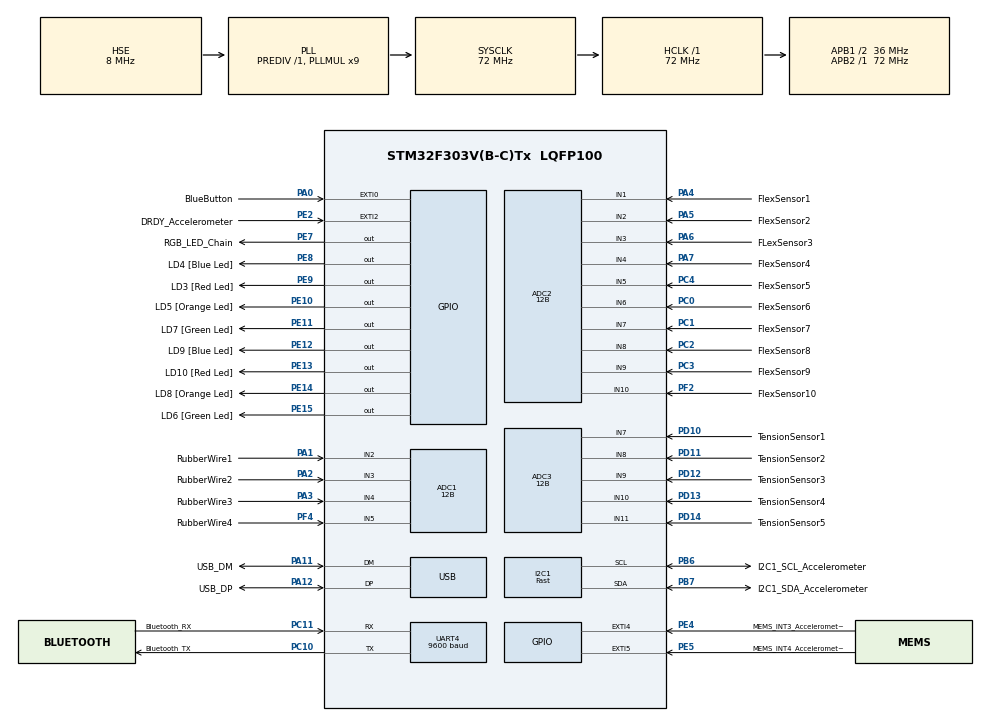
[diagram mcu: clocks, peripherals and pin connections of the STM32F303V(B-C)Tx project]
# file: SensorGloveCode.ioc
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ADC1.Channel-0\#ChannelRegularConversion=ADC_CHANNEL_2
ADC1.Channel-1\#ChannelRegularConversion=ADC_CHANNEL_3
ADC1.Channel-2\#ChannelRegularConversion=ADC_CHANNEL_4
ADC1.Channel-3\#ChannelRegularConversion=ADC_CHANNEL_5
ADC1.ClockPrescaler=ADC_CLOCK_SYNC_PCLK_DIV1
ADC1.ContinuousConvMode=ENABLE
ADC1.DMAContinuousRequests=ENABLE
ADC1.DataAlign=ADC_DATAALIGN_RIGHT
ADC1.DiscontinuousConvMode=DISABLE
ADC1.EOCSelection=ADC_EOC_SEQ_CONV
ADC1.EnableAnalogWatchDog1=false
ADC1.EnableAnalogWatchDog2=false
ADC1.EnableAnalogWatchDog3=false
ADC1.EnableInjectedConversion=ENABLE
ADC1.EnableRegularConversion=ENABLE
ADC1.ExternalTrigConv=ADC_SOFTWARE_START
ADC1.ExternalTrigConvEdge=ADC_EXTERNALTRIGCONVEDGE_NONE
ADC1.InjNumberOfConversion=0
ADC1.LowPowerAutoWait=DISABLE
ADC1.NbrOfConversion=4
ADC1.NbrOfConversionFlag=1
ADC1.Offset-0\#ChannelRegularConversion=0
ADC1.Offset-1\#ChannelRegularConversion=0
ADC1.Offset-2\#ChannelRegularConversion=0
ADC1.Offset-3\#ChannelRegularConversion=0
ADC1.OffsetNumber-0\#ChannelRegularConversion=ADC_OFFSET_NONE
ADC1.OffsetNumber-1\#ChannelRegularConversion=ADC_OFFSET_NONE
ADC1.OffsetNumber-2\#ChannelRegularConversion=ADC_OFFSET_NONE
ADC1.OffsetNumber-3\#ChannelRegularConversion=ADC_OFFSET_NONE
ADC1.Overrun=ADC_OVR_DATA_OVERWRITTEN
ADC1.Rank-0\#ChannelRegularConversion=1
ADC1.Rank-1\#ChannelRegularConversion=2
ADC1.Rank-2\#ChannelRegularConversion=3
ADC1.Rank-3\#ChannelRegularConversion=4
ADC1.Resolution=ADC_RESOLUTION_12B
ADC1.SamplingTime-0\#ChannelRegularConversion=ADC_SAMPLETIME_181CYCLES_5
ADC1.SamplingTime-1\#ChannelRegularConversion=ADC_SAMPLETIME_181CYCLES_5
ADC1.SamplingTime-2\#ChannelRegularConversion=ADC_SAMPLETIME_181CYCLES_5
ADC1.SamplingTime-3\#ChannelRegularConversion=ADC_SAMPLETIME_181CYCLES_5
ADC1.ScanConvMode=ADC_SCAN_ENABLE
ADC1.master=1
ADC2.Channel-0\#ChannelRegularConversion=ADC_CHANNEL_1
ADC2.Channel-1\#ChannelRegularConversion=ADC_CHANNEL_2
ADC2.Channel-2\#ChannelRegularConversion=ADC_CHANNEL_3
ADC2.Channel-3\#ChannelRegularConversion=ADC_CHANNEL_4
ADC2.Channel-4\#ChannelRegularConversion=ADC_CHANNEL_5
ADC2.Channel-5\#ChannelRegularConversion=ADC_CHANNEL_6
ADC2.Channel-6\#ChannelRegularConversion=ADC_CHANNEL_7
ADC2.Channel-7\#ChannelRegularConversion=ADC_CHANNEL_8
ADC2.Channel-8\#ChannelRegularConversion=ADC_CHANNEL_9
ADC2.Channel-9\#ChannelRegularConversion=ADC_CHANNEL_10
ADC2.ClockPrescaler=ADC_CLOCK_SYNC_PCLK_DIV1
ADC2.ContinuousConvMode=ENABLE
ADC2.DMAContinuousRequests=ENABLE
ADC2.DataAlign=ADC_DATAALIGN_RIGHT
ADC2.DiscontinuousConvMode=DISABLE
ADC2.EOCSelection=ADC_EOC_SEQ_CONV
ADC2.EnableAnalogWatchDog1=false
ADC2.EnableAnalogWatchDog2=false
ADC2.EnableAnalogWatchDog3=false
ADC2.EnableInjectedConversion=ENABLE
ADC2.EnableRegularConversion=ENABLE
ADC2.ExternalTrigConv=ADC_SOFTWARE_START
ADC2.ExternalTrigConvEdge=ADC_EXTERNALTRIGCONVEDGE_NONE
ADC2.InjNumberOfConversion=0
ADC2.LowPowerAutoWait=DISABLE
ADC2.NbrOfConversion=10
ADC2.NbrOfConversionFlag=1
ADC2.Offset-0\#ChannelRegularConversion=0
ADC2.Offset-1\#ChannelRegularConversion=0
ADC2.Offset-2\#ChannelRegularConversion=0
ADC2.Offset-3\#ChannelRegularConversion=0
ADC2.Offset-4\#ChannelRegularConversion=0
ADC2.Offset-5\#ChannelRegularConversion=0
ADC2.Offset-6\#ChannelRegularConversion=0
ADC2.Offset-7\#ChannelRegularConversion=0
ADC2.Offset-8\#ChannelRegularConversion=0
ADC2.Offset-9\#ChannelRegularConversion=0
ADC2.OffsetNumber-0\#ChannelRegularConversion=ADC_OFFSET_NONE
ADC2.OffsetNumber-1\#ChannelRegularConversion=ADC_OFFSET_NONE
ADC2.OffsetNumber-2\#ChannelRegularConversion=ADC_OFFSET_NONE
ADC2.OffsetNumber-3\#ChannelRegularConversion=ADC_OFFSET_NONE
ADC2.OffsetNumber-4\#ChannelRegularConversion=ADC_OFFSET_NONE
ADC2.OffsetNumber-5\#ChannelRegularConversion=ADC_OFFSET_NONE
ADC2.OffsetNumber-6\#ChannelRegularConversion=ADC_OFFSET_NONE
ADC2.OffsetNumber-7\#ChannelRegularConversion=ADC_OFFSET_NONE
ADC2.OffsetNumber-8\#ChannelRegularConversion=ADC_OFFSET_NONE
ADC2.OffsetNumber-9\#ChannelRegularConversion=ADC_OFFSET_NONE
ADC2.Overrun=ADC_OVR_DATA_OVERWRITTEN
ADC2.Rank-0\#ChannelRegularConversion=1
ADC2.Rank-1\#ChannelRegularConversion=2
ADC2.Rank-2\#ChannelRegularConversion=3
ADC2.Rank-3\#ChannelRegularConversion=4
ADC2.Rank-4\#ChannelRegularConversion=5
ADC2.Rank-5\#ChannelRegularConversion=6
ADC2.Rank-6\#ChannelRegularConversion=7
ADC2.Rank-7\#ChannelRegularConversion=8
ADC2.Rank-8\#ChannelRegularConversion=9
ADC2.Rank-9\#ChannelRegularConversion=10
ADC2.Resolution=ADC_RESOLUTION_12B
ADC2.SamplingTime-0\#ChannelRegularConversion=ADC_SAMPLETIME_181CYCLES_5
ADC2.SamplingTime-1\#ChannelRegularConversion=ADC_SAMPLETIME_181CYCLES_5
ADC2.SamplingTime-2\#ChannelRegularConversion=ADC_SAMPLETIME_181CYCLES_5
ADC2.SamplingTime-3\#ChannelRegularConversion=ADC_SAMPLETIME_181CYCLES_5
ADC2.SamplingTime-4\#ChannelRegularConversion=ADC_SAMPLETIME_181CYCLES_5
ADC2.SamplingTime-5\#ChannelRegularConversion=ADC_SAMPLETIME_181CYCLES_5
ADC2.SamplingTime-6\#ChannelRegularConversion=ADC_SAMPLETIME_181CYCLES_5
ADC2.SamplingTime-7\#ChannelRegularConversion=ADC_SAMPLETIME_181CYCLES_5
ADC2.SamplingTime-8\#ChannelRegularConversion=ADC_SAMPLETIME_181CYCLES_5
ADC2.SamplingTime-9\#ChannelRegularConversion=ADC_SAMPLETIME_181CYCLES_5
ADC2.ScanConvMode=ADC_SCAN_ENABLE
ADC3.Channel-13\#ChannelRegularConversion=ADC_CHANNEL_7
ADC3.Channel-14\#ChannelRegularConversion=ADC_CHANNEL_8
ADC3.Channel-15\#ChannelRegularConversion=ADC_CHANNEL_9
ADC3.Channel-16\#ChannelRegularConversion=ADC_CHANNEL_10
ADC3.Channel-17\#ChannelRegularConversion=ADC_CHANNEL_11
ADC3.ClockPrescaler=ADC_CLOCK_SYNC_PCLK_DIV1
ADC3.ContinuousConvMode=ENABLE
ADC3.DMAContinuousRequests=ENABLE
ADC3.DataAlign=ADC_DATAALIGN_RIGHT
ADC3.DiscontinuousConvMode=DISABLE
ADC3.EOCSelection=ADC_EOC_SEQ_CONV
ADC3.EnableAnalogWatchDog1=false
ADC3.EnableAnalogWatchDog2=false
ADC3.EnableAnalogWatchDog3=false
ADC3.EnableInjectedConversion=ENABLE
ADC3.EnableRegularConversion=ENABLE
ADC3.ExternalTrigConv=ADC_SOFTWARE_START
ADC3.ExternalTrigConvEdge=ADC_EXTERNALTRIGCONVEDGE_NONE
ADC3.InjNumberOfConversion=0
ADC3.LowPowerAutoWait=DISABLE
ADC3.NbrOfConversion=5
ADC3.NbrOfConversionFlag=1
ADC3.Offset-13\#ChannelRegularConversion=0
ADC3.Offset-14\#ChannelRegularConversion=0
ADC3.Offset-15\#ChannelRegularConversion=0
ADC3.Offset-16\#ChannelRegularConversion=0
ADC3.Offset-17\#ChannelRegularConversion=0
ADC3.OffsetNumber-13\#ChannelRegularConversion=ADC_OFFSET_NONE
ADC3.OffsetNumber-14\#ChannelRegularConversion=ADC_OFFSET_NONE
ADC3.OffsetNumber-15\#ChannelRegularConversion=ADC_OFFSET_NONE
ADC3.OffsetNumber-16\#ChannelRegularConversion=ADC_OFFSET_NONE
ADC3.OffsetNumber-17\#ChannelRegularConversion=ADC_OFFSET_NONE
ADC3.Overrun=ADC_OVR_DATA_OVERWRITTEN
ADC3.Rank-13\#ChannelRegularConversion=1
ADC3.Rank-14\#ChannelRegularConversion=2
ADC3.Rank-15\#ChannelRegularConversion=3
ADC3.Rank-16\#ChannelRegularConversion=4
ADC3.Rank-17\#ChannelRegularConversion=5
ADC3.Resolution=ADC_RESOLUTION_12B
ADC3.SamplingTime-13\#ChannelRegularConversion=ADC_SAMPLETIME_181CYCLES_5
ADC3.SamplingTime-14\#ChannelRegularConversion=ADC_SAMPLETIME_181CYCLES_5
ADC3.SamplingTime-15\#ChannelRegularConversion=ADC_SAMPLETIME_181CYCLES_5
ADC3.SamplingTime-16\#ChannelRegularConversion=ADC_SAMPLETIME_181CYCLES_5
ADC3.SamplingTime-17\#ChannelRegularConversion=ADC_SAMPLETIME_181CYCLES_5
ADC3.ScanConvMode=ADC_SCAN_ENABLE
ADC3.master=1
Dma.ADC1.2.Direction=DMA_PERIPH_TO_MEMORY
Dma.ADC1.2.Instance=DMA1_Channel1
Dma.ADC1.2.MemDataAlignment=DMA_MDATAALIGN_HALFWORD
Dma.ADC1.2.MemInc=DMA_MINC_ENABLE
Dma.ADC1.2.Mode=DMA_CIRCULAR
Dma.ADC1.2.PeriphDataAlignment=DMA_PDATAALIGN_HALFWORD
Dma.ADC1.2.PeriphInc=DMA_PINC_DISABLE
Dma.ADC1.2.Priority=DMA_PRIORITY_LOW
Dma.ADC2.1.Direction=DMA_PERIPH_TO_MEMORY
Dma.ADC2.1.Instance=DMA2_Channel3
Dma.ADC2.1.MemDataAlignment=DMA_MDATAALIGN_HALFWORD
Dma.ADC2.1.MemInc=DMA_MINC_ENABLE
Dma.ADC2.1.Mode=DMA_CIRCULAR
Dma.ADC2.1.PeriphDataAlignment=DMA_PDATAALIGN_HALFWORD
Dma.ADC2.1.PeriphInc=DMA_PINC_DISABLE
Dma.ADC2.1.Priority=DMA_PRIORITY_LOW
Dma.ADC3.0.Direction=DMA_PERIPH_TO_MEMORY
Dma.ADC3.0.Instance=DMA2_Channel5
Dma.ADC3.0.MemDataAlignment=DMA_MDATAALIGN_HALFWORD
Dma.ADC3.0.MemInc=DMA_MINC_ENABLE
Dma.ADC3.0.Mode=DMA_CIRCULAR
Dma.ADC3.0.PeriphDataAlignment=DMA_PDATAALIGN_HALFWORD
Dma.ADC3.0.PeriphInc=DMA_PINC_DISABLE
Dma.ADC3.0.Priority=DMA_PRIORITY_LOW
Dma.Request0=ADC3
Dma.Request1=ADC2
Dma.Request2=ADC1
I2C1.I2C_Speed_Mode=I2C_Fast
I2C1.Speed=I2C_ClockSpeed_kHz
I2C1.Timing=0x0000020B
Mcu.Family=STM32F3
Mcu.Name=STM32F303V(B-C)Tx
Mcu.Package=LQFP100
Mcu.UserConstants=I2C_ClockSpeed_kHz,400;TIM6_PRESCALER,71;TIM6_COUNTER_PERIOD,99;TIM7_PRESCALER,719;TIM7_COUNTER_PERIOD,99
NVIC.DMA1_Channel1_IRQn=true\:0\:0\:false\:false\:true
NVIC.DMA2_Channel3_IRQn=true\:0\:0\:false\:false\:true
NVIC.DMA2_Channel5_IRQn=true\:0\:0\:false\:false\:true
NVIC.EXTI0_IRQn=true\:0\:0\:false\:false\:true
NVIC.PriorityGroup=NVIC_PRIORITYGROUP_0
NVIC.TIM6_DAC_IRQn=true\:0\:0\:false\:false\:true
NVIC.TIM7_IRQn=true\:0\:0\:false\:false\:true
NVIC.UART4_IRQn=true\:0\:0\:false\:false\:true
NVIC.USB_LP_CAN_RX0_IRQn=true\:0\:0\:false\:false\:true
PA0.GPIO_Label=BlueButton
PA0.GPIO_ModeDefaultEXTI=GPIO_MODE_IT_RISING
PA0.GPIO_PuPd=GPIO_PULLDOWN
PA0.Signal=GPXTI0
PA1.GPIO_Label=RubberWire1
PA1.Mode=IN2-Single-Ended
PA1.Signal=ADC1_IN2
PA11.GPIO_Label=USB_DM
PA11.Mode=Device
PA11.Signal=USB_DM
PA12.GPIO_Label=USB_DP
PA12.Mode=Device
PA12.Signal=USB_DP
PA13.GPIO_Label=SWDIO
PA13.Mode=Serial_Wire
PA13.Signal=SYS_JTMS-SWDIO
PA14.GPIO_Label=SWCLK
PA14.Mode=Serial_Wire
PA14.Signal=SYS_JTCK-SWCLK
PA2.GPIO_Label=RubberWire2
PA2.Mode=IN3-Single-Ended
PA2.Signal=ADC1_IN3
PA3.GPIO_Label=RubberWire3
PA3.Mode=IN4-Single-Ended
PA3.Signal=ADC1_IN4
PA4.GPIO_Label=FlexSensor1
PA4.Mode=IN1-Single-Ended
PA4.Signal=ADC2_IN1
PA5.GPIO_Label=FlexSensor2
PA5.Mode=IN2-Single-Ended
PA5.Signal=ADC2_IN2
PA6.GPIO_Label=FLexSensor3
PA6.Mode=IN3-Single-Ended
PA6.Signal=ADC2_IN3
PA7.GPIO_Label=FlexSensor4
PA7.Mode=IN4-Single-Ended
PA7.Signal=ADC2_IN4
PB6.GPIO_FM6=__NULL
PB6.GPIO_Label=I2C1_SCL_Accelerometer
PB6.GPIO_Mode=GPIO_MODE_AF_OD
PB6.GPIO_PuPd=GPIO_NOPULL
PB6.GPIO_Speed=GPIO_SPEED_FREQ_LOW
PB6.Mode=I2C
PB6.Signal=I2C1_SCL
PB7.GPIO_FM7=__NULL
PB7.GPIO_Label=I2C1_SDA_Accelerometer
PB7.GPIO_Mode=GPIO_MODE_AF_OD
PB7.GPIO_PuPd=GPIO_NOPULL
PB7.GPIO_Speed=GPIO_SPEED_FREQ_LOW
PB7.Mode=I2C
PB7.Signal=I2C1_SDA
PC0.GPIO_Label=FlexSensor6
PC0.Signal=ADCx_IN6
PC1.GPIO_Label=FlexSensor7
PC1.Signal=ADCx_IN7
PC10.GPIO_Label=Bluetooth_TX
PC10.Mode=Asynchronous
PC10.Signal=UART4_TX
PC11.GPIO_Label=Bluetooth_RX
PC11.Mode=Asynchronous
PC11.Signal=UART4_RX
PC2.GPIO_Label=FlexSensor8
PC2.Signal=ADCx_IN8
PC3.GPIO_Label=FlexSensor9
PC3.Signal=ADCx_IN9
PC4.GPIO_Label=FlexSensor5
PC4.Mode=IN5-Single-Ended
PC4.Signal=ADC2_IN5
PD10.GPIO_Label=TensionSensor1
PD10.Signal=ADCx_IN7P
PD11.GPIO_Label=TensionSensor2
PD11.Signal=ADCx_IN8P
PD12.GPIO_Label=TensionSensor3
PD12.Signal=ADCx_IN9P
PD13.GPIO_Label=TensionSensor4
PD13.Signal=ADCx_IN10P
PD14.GPIO_Label=TensionSensor5
PD14.Signal=ADCx_IN11
PE10.GPIO_Label=LD5 [Orange Led]
PE10.GPIO_ModeDefaultOutputPP=GPIO_MODE_OUTPUT_PP
PE10.GPIO_PuPd=GPIO_NOPULL
PE10.GPIO_Speed=GPIO_SPEED_FREQ_LOW
PE10.Signal=GPIO_Output
PE11.GPIO_Label=LD7 [Green Led]
PE11.GPIO_ModeDefaultOutputPP=GPIO_MODE_OUTPUT_PP
PE11.GPIO_PuPd=GPIO_NOPULL
PE11.GPIO_Speed=GPIO_SPEED_FREQ_LOW
PE11.Signal=GPIO_Output
PE12.GPIO_Label=LD9 [Blue Led]
PE12.GPIO_ModeDefaultOutputPP=GPIO_MODE_OUTPUT_PP
PE12.GPIO_PuPd=GPIO_NOPULL
PE12.GPIO_Speed=GPIO_SPEED_FREQ_LOW
PE12.Signal=GPIO_Output
PE13.GPIO_Label=LD10 [Red Led]
PE13.GPIO_ModeDefaultOutputPP=GPIO_MODE_OUTPUT_PP
PE13.GPIO_PuPd=GPIO_NOPULL
PE13.GPIO_Speed=GPIO_SPEED_FREQ_LOW
PE13.Signal=GPIO_Output
PE14.GPIO_Label=LD8 [Orange Led]
PE14.GPIO_ModeDefaultOutputPP=GPIO_MODE_OUTPUT_PP
PE14.GPIO_PuPd=GPIO_NOPULL
PE14.GPIO_Speed=GPIO_SPEED_FREQ_LOW
PE14.Signal=GPIO_Output
PE15.GPIO_Label=LD6 [Green Led]
PE15.GPIO_ModeDefaultOutputPP=GPIO_MODE_OUTPUT_PP
PE15.GPIO_PuPd=GPIO_NOPULL
PE15.GPIO_Speed=GPIO_SPEED_FREQ_LOW
PE15.Signal=GPIO_Output
PE2.GPIO_Label=DRDY_Accelerometer
PE2.GPIO_ModeDefaultEXTI=GPIO_MODE_EVT_RISING
PE2.GPIO_PuPd=GPIO_NOPULL
PE2.Signal=GPXTI2
PE4.GPIO_Label=MEMS_INT3_Accelerometer
PE4.GPIO_ModeDefaultEXTI=GPIO_MODE_EVT_RISING
PE4.GPIO_PuPd=GPIO_NOPULL
PE4.Signal=GPXTI4
PE5.GPIO_Label=MEMS_INT4_Accelerometer
PE5.GPIO_ModeDefaultEXTI=GPIO_MODE_EVT_RISING
PE5.GPIO_PuPd=GPIO_NOPULL
PE5.Signal=GPXTI5
PE7.GPIO_Label=RGB_LED_Chain
PE7.Signal=GPIO_Output
PE8.GPIO_Label=LD4 [Blue Led]
PE8.GPIO_ModeDefaultOutputPP=GPIO_MODE_OUTPUT_PP
PE8.GPIO_PuPd=GPIO_NOPULL
PE8.GPIO_Speed=GPIO_SPEED_FREQ_LOW
PE8.Signal=GPIO_Output
PE9.GPIO_Label=LD3 [Red Led]
PE9.GPIO_ModeDefaultOutputPP=GPIO_MODE_OUTPUT_PP
PE9.GPIO_PuPd=GPIO_NOPULL
PE9.GPIO_Speed=GPIO_SPEED_FREQ_LOW
PE9.Signal=GPIO_Output
PF0-OSC_IN.GPIO_Label=OSC_IN
PF0-OSC_IN.Mode=HSE-External-Oscillator
PF0-OSC_IN.Signal=RCC_OSC_IN
PF1-OSC_OUT.GPIO_Label=OSC_OUT
PF1-OSC_OUT.Mode=HSE-External-Oscillator
PF1-OSC_OUT.Signal=RCC_OSC_OUT
PF2.GPIO_Label=FlexSensor10
PF2.Signal=ADCx_IN10
PF4.GPIO_Label=RubberWire4
PF4.Mode=IN5-Single-Ended
PF4.Signal=ADC1_IN5
ProjectManager.HeapSize=0x200
ProjectManager.StackSize=0x400
ProjectManager.TargetToolchain=TrueSTUDIO
RCC.ADC12PRES=RCC_ADC12PLLCLK_DIV1
RCC.ADC34PRES=RCC_ADC34PLLCLK_DIV1
RCC.AHBCLKDivider=RCC_SYSCLK_DIV1
RCC.AHBFreq_Value=72000000
RCC.APB1CLKDivider=RCC_HCLK_DIV2
RCC.APB1Freq_Value=36000000
RCC.APB1TimFreq_Value=72000000
RCC.APB2CLKDivider=RCC_HCLK_DIV1
RCC.APB2Freq_Value=72000000
RCC.APB2TimFreq_Value=72000000
RCC.CortexFreq_Value=72000000
RCC.Cortex_Div=SYSTICK_CLKSOURCE_HCLK
RCC.HCLKFreq_Value=72000000
RCC.HSE_VALUE=8000000
RCC.HSI_VALUE=8000000
RCC.LSE_VALUE=32768
RCC.PLLMUL=RCC_PLL_MUL9
RCC.PRESCALERUSB=RCC_USBCLKSOURCE_PLL_DIV1_5
RCC.RCC_PLLsource_Clock_Source_FROM_HSE=RCC_HSE_PREDIV_DIV1
RCC.SYSCLKFreq_VALUE=72000000
RCC.SYSCLKSourceVirtual=RCC_SYSCLKSOURCE_PLLCLK
RCC.USBFreq_Value=48000000
SH.ADCx_IN10.0=ADC2_IN10,IN10-Single-Ended
SH.ADCx_IN10P.0=ADC3_IN10,IN10-Single-Ended
SH.ADCx_IN11.0=ADC3_IN11,IN11-Single-Ended
SH.ADCx_IN6.0=ADC2_IN6,IN6-Single-Ended
SH.ADCx_IN7.0=ADC2_IN7,IN7-Single-Ended
SH.ADCx_IN7P.0=ADC3_IN7,IN7-Single-Ended
SH.ADCx_IN8.0=ADC2_IN8,IN8-Single-Ended
SH.ADCx_IN8P.0=ADC3_IN8,IN8-Single-Ended
SH.ADCx_IN9.0=ADC2_IN9,IN9-Single-Ended
SH.ADCx_IN9P.0=ADC3_IN9,IN9-Single-Ended
TIM6.Period=TIM6_COUNTER_PERIOD
TIM6.Prescaler=TIM6_PRESCALER
TIM7.Period=TIM7_COUNTER_PERIOD
TIM7.Prescaler=TIM7_PRESCALER
UART4.BaudRate=9600
UART4.Mode=MODE_TX
USB_DEVICE.CLASS_NAME_FS=CDC
USB_DEVICE.VirtualMode=Cdc
USB_DEVICE.VirtualModeFS=Cdc_FS
VP_TIM6_VS_ClockSourceINT.Mode=Enable_Timer
VP_TIM7_VS_ClockSourceINT.Mode=Enable_Timer
VP_USB_DEVICE_VS_USB_DEVICE_CDC_FS.Mode=CDC_FS
board=STM32F3DISCOVERY

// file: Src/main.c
/**
  ******************************************************************************
  * File Name          : main.c
  * Description        : Main program body
  ******************************************************************************
  *
  * Copyright (c) 2017 STMicroelectronics International N.V.
  * All rights reserved.
  *
  * Redistribution and use in source and binary forms, with or without
  * modification, are permitted, provided that the following conditions are met:
  *
  * 1. Redistribution of source code must retain the above copyright notice,
  *    this list of conditions and the following disclaimer.
  * 2. Redistributions in binary form must reproduce the above copyright notice,
  *    this list of conditions and the following disclaimer in the documentation
  *    and/or other materials provided with the distribution.
  * 3. Neither the name of STMicroelectronics nor the names of other
  *    contributors to this software may be used to endorse or promote products
  *    derived from this software without specific written permission.
  * 4. This software, including modifications and/or derivative works of this
  *    software, must execute solely and exclusively on microcontroller or
  *    microprocessor devices manufactured by or for STMicroelectronics.
  * 5. Redistribution and use of this software other than as permitted under
  *    this license is void and will automatically terminate your rights under
  *    this license.
  *
  * THIS SOFTWARE IS PROVIDED BY STMICROELECTRONICS AND CONTRIBUTORS "AS IS"
  * AND ANY EXPRESS, IMPLIED OR STATUTORY WARRANTIES, INCLUDING, BUT NOT
  * LIMITED TO, THE IMPLIED WARRANTIES OF MERCHANTABILITY, FITNESS FOR A
  * PARTICULAR PURPOSE AND NON-INFRINGEMENT OF THIRD PARTY INTELLECTUAL PROPERTY
  * RIGHTS ARE DISCLAIMED TO THE FULLEST EXTENT PERMITTED BY LAW. IN NO EVENT
  * SHALL STMICROELECTRONICS OR CONTRIBUTORS BE LIABLE FOR ANY DIRECT, INDIRECT,
  * INCIDENTAL, SPECIAL, EXEMPLARY, OR CONSEQUENTIAL DAMAGES (INCLUDING, BUT NOT
  * LIMITED TO, PROCUREMENT OF SUBSTITUTE GOODS OR SERVICES; LOSS OF USE, DATA,
  * OR PROFITS; OR BUSINESS INTERRUPTION) HOWEVER CAUSED AND ON ANY THEORY OF
  * LIABILITY, WHETHER IN CONTRACT, STRICT LIABILITY, OR TORT (INCLUDING
  * NEGLIGENCE OR OTHERWISE) ARISING IN ANY WAY OUT OF THE USE OF THIS SOFTWARE,
  * EVEN IF ADVISED OF THE POSSIBILITY OF SUCH DAMAGE.
  *
  ******************************************************************************
  */
#include "main.h"
#include "stm32f3xx_hal.h"
#include "adc.h"
#include "dma.h"
#include "i2c.h"
#include "tim.h"
#include "usart.h"
#include "usb_device.h"
#include "gpio.h"

/* USER CODE BEGIN Includes */
#include "usbd_cdc_if.h"
#include "MeasurementStruct.h"
#include "Measurements.h"
#include "Accelerometer.h"
#include "DataProcessing.h"
#include "Transmission.h"
/* USER CODE END Includes */

/* USER CODE BEGIN PV */
/* Private variables ---------------------------------------------------------*/

/* USER CODE END PV */

void SystemClock_Config(void);
void Error_Handler(void);

/* USER CODE BEGIN PFP */
/* Private function prototypes -----------------------------------------------*/

/* USER CODE END PFP */

int main(void)
{

  /* MCU Configuration----------------------------------------------------------*/

  /* Reset of all peripherals, Initializes the Flash interface and the Systick. */
  HAL_Init();

  /* Configure the system clock */
  SystemClock_Config();

  /* Initialize all configured peripherals */
  MX_GPIO_Init();
  MX_DMA_Init();
  MX_ADC1_Init();
  MX_ADC2_Init();
  MX_ADC3_Init();
  MX_I2C1_Init();
  MX_UART4_Init();
  MX_TIM6_Init();
  MX_TIM7_Init();
  MX_USB_DEVICE_Init();

  /* USER CODE BEGIN 2 */
  StartMeasurementsDMA();
  StartAccelerometerMeasurements();
  StartTransmission();

  /* USER CODE END 2 */

  /* Infinite loop */
  /* USER CODE BEGIN WHILE */
  while (1)
  {
	  GetAccelerometerData();
	  AggregateMeasurements();
	  ContinueTransmission();
  /* USER CODE END WHILE */

  }

}

/** System Clock Configuration
*/
void SystemClock_Config(void)
{

  RCC_OscInitTypeDef RCC_OscInitStruct;
  RCC_ClkInitTypeDef RCC_ClkInitStruct;
  RCC_PeriphCLKInitTypeDef PeriphClkInit;

    /**Initializes the CPU, AHB and APB busses clocks
    */
  RCC_OscInitStruct.OscillatorType = RCC_OSCILLATORTYPE_HSI|RCC_OSCILLATORTYPE_HSE;
  RCC_OscInitStruct.HSEState = RCC_HSE_ON;
  RCC_OscInitStruct.HSEPredivValue = RCC_HSE_PREDIV_DIV1;
  RCC_OscInitStruct.HSIState = RCC_HSI_ON;
  RCC_OscInitStruct.HSICalibrationValue = 16;
  RCC_OscInitStruct.PLL.PLLState = RCC_PLL_ON;
  RCC_OscInitStruct.PLL.PLLSource = RCC_PLLSOURCE_HSE;
  RCC_OscInitStruct.PLL.PLLMUL = RCC_PLL_MUL9;
  if (HAL_RCC_OscConfig(&RCC_OscInitStruct) != HAL_OK)
  {
    Error_Handler();
  }

    /**Initializes the CPU, AHB and APB busses clocks
    */
  RCC_ClkInitStruct.ClockType = RCC_CLOCKTYPE_HCLK|RCC_CLOCKTYPE_SYSCLK
                              |RCC_CLOCKTYPE_PCLK1|RCC_CLOCKTYPE_PCLK2;
  RCC_ClkInitStruct.SYSCLKSource = RCC_SYSCLKSOURCE_PLLCLK;
  RCC_ClkInitStruct.AHBCLKDivider = RCC_SYSCLK_DIV1;
  RCC_ClkInitStruct.APB1CLKDivider = RCC_HCLK_DIV2;
  RCC_ClkInitStruct.APB2CLKDivider = RCC_HCLK_DIV1;

  if (HAL_RCC_ClockConfig(&RCC_ClkInitStruct, FLASH_LATENCY_2) != HAL_OK)
  {
    Error_Handler();
  }

  PeriphClkInit.PeriphClockSelection = RCC_PERIPHCLK_USB|RCC_PERIPHCLK_UART4
                              |RCC_PERIPHCLK_I2C1;
  PeriphClkInit.Uart4ClockSelection = RCC_UART4CLKSOURCE_PCLK1;
  PeriphClkInit.I2c1ClockSelection = RCC_I2C1CLKSOURCE_HSI;
  PeriphClkInit.USBClockSelection = RCC_USBCLKSOURCE_PLL_DIV1_5;
  if (HAL_RCCEx_PeriphCLKConfig(&PeriphClkInit) != HAL_OK)
  {
    Error_Handler();
  }

    /**Configure the Systick interrupt time
    */
  HAL_SYSTICK_Config(HAL_RCC_GetHCLKFreq()/1000);

    /**Configure the Systick
    */
  HAL_SYSTICK_CLKSourceConfig(SYSTICK_CLKSOURCE_HCLK);

  /* SysTick_IRQn interrupt configuration */
  HAL_NVIC_SetPriority(SysTick_IRQn, 0, 0);
}

void Error_Handler(void)
{
  /* USER CODE BEGIN Error_Handler */
  /* User can add his own implementation to report the HAL error return state */
	HAL_GPIO_WritePin(LD3_GPIO_Port,LD3_Pin,GPIO_PIN_SET);
  /* USER CODE END Error_Handler */
}

/************************ (C) COPYRIGHT STMicroelectronics *****END OF FILE****/
